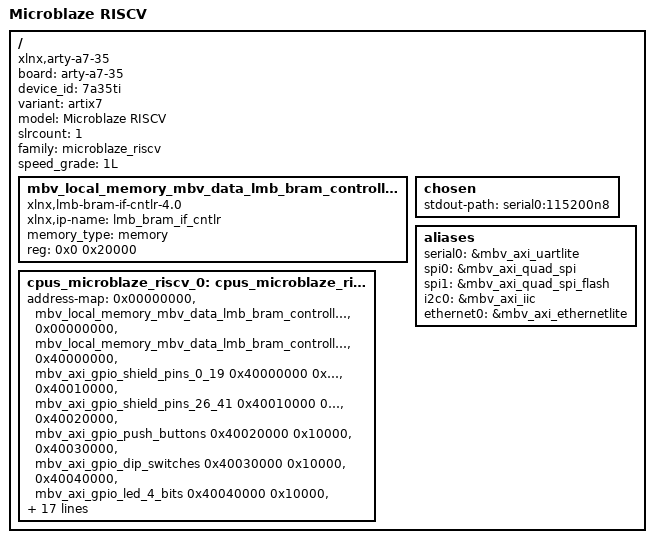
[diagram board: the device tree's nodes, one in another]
/dts-v1/;
#include "pl.dtsi"
/ {
	board = "arty-a7-35";
	compatible = "xlnx,arty-a7-35";
	device_id = "7a35ti";
	#address-cells = <1>;
	variant = "artix7";
	model = "Microblaze RISCV";
	#size-cells = <1>;
	slrcount = <1>;
	family = "microblaze_riscv";
	speed_grade = "1L";
	mbv_local_memory_mbv_data_lmb_bram_controller_memory: memory@0 {
		compatible = "xlnx,lmb-bram-if-cntlr-4.0";
		xlnx,ip-name = "lmb_bram_if_cntlr";
		device_type = "memory";
		memory_type = "memory";
		reg = <0x0 0x20000>;
	};
	chosen {
		stdout-path = "serial0:115200n8";
	};
	aliases {
		serial0 = &mbv_axi_uartlite;
		spi0 = &mbv_axi_quad_spi;
		spi1 = &mbv_axi_quad_spi_flash;
		i2c0 = &mbv_axi_iic;
		ethernet0 = &mbv_axi_ethernetlite;
	};
	cpus_microblaze_riscv_0: cpus_microblaze_riscv@0 {
		address-map = <0x00000000 &mbv_local_memory_mbv_data_lmb_bram_controller_memory 0x00000000 0x20000>, 
			      <0x00000000 &mbv_local_memory_mbv_data_lmb_bram_controller 0x00000000 0x20000>, 
			      <0x40000000 &mbv_axi_gpio_shield_pins_0_19 0x40000000 0x10000>, 
			      <0x40010000 &mbv_axi_gpio_shield_pins_26_41 0x40010000 0x10000>, 
			      <0x40020000 &mbv_axi_gpio_push_buttons 0x40020000 0x10000>, 
			      <0x40030000 &mbv_axi_gpio_dip_switches 0x40030000 0x10000>, 
			      <0x40040000 &mbv_axi_gpio_led_4_bits 0x40040000 0x10000>, 
			      <0x40050000 &mbv_axi_gpio_led_rgb 0x40050000 0x10000>, 
			      <0x40060000 &mbv_axi_gpio_iic_pullups 0x40060000 0x10000>, 
			      <0x40600000 &mbv_axi_uartlite 0x40600000 0x10000>, 
			      <0x40800000 &mbv_axi_iic 0x40800000 0x10000>, 
			      <0x40e00000 &mbv_axi_ethernetlite 0x40e00000 0x10000>, 
			      <0x41200000 &mbv_axi_interrupt_controller 0x41200000 0x10000>, 
			      <0x41a00000 &mbv_axi_timebase_watchdog_timer 0x41a00000 0x10000>, 
			      <0x44a00000 &mbv_axi_quad_spi_flash 0x44a00000 0x10000>, 
			      <0x44a10000 &mbv_axi_quad_spi 0x44a10000 0x10000>;
		#ranges-address-cells = <0x1>;
		#ranges-size-cells = <0x1>;
	};
};
